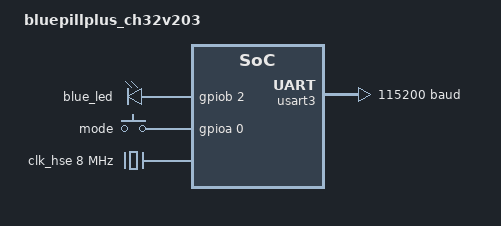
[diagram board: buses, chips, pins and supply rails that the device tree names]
/*
 * Copyright (c) 2025 MASSDRIVER EI (massdriver.space)
 * SPDX-License-Identifier: Apache-2.0
 */

/dts-v1/;

#include <wch/ch32v203/ch32v203c8t.dtsi>
#include <zephyr/dt-bindings/gpio/gpio.h>
#include <zephyr/dt-bindings/input/input-event-codes.h>
#include "bluepillplus_ch32v203-pinctrl.dtsi"

/ {
	model = "bluepillplus_ch32v203";
	compatible = "wch,ch32v203";

	chosen {
		zephyr,sram = &sram0;
		zephyr,flash = &flash0;
		zephyr,console = &usart3;
		zephyr,shell-uart = &usart3;
	};

	leds {
		compatible = "gpio-leds";
		status = "okay";

		blue_led: led0 {
			gpios = <&gpiob 2 GPIO_ACTIVE_HIGH>;
		};
	};

	buttons {
		compatible = "gpio-keys";

		mode: sw0 {
			gpios = <&gpioa 0 GPIO_ACTIVE_HIGH>;
			zephyr,code = <INPUT_KEY_0>;
		};
	};

	aliases {
		led0 = &blue_led;
		sw0 = &mode;
	};
};

&clk_hse {
	clock-frequency = <DT_FREQ_M(8)>;
	status = "okay";
};

&pll {
	clocks = <&clk_hse>;
	status = "okay";
};

&rcc {
	clocks = <&pll>;
};

&gpioa {
	status = "okay";
};

&gpiob {
	status = "okay";
};

&gpioc {
	status = "okay";
};

&usart3 {
	status = "okay";
	current-speed = <115200>;
	pinctrl-0 = <&usart3_default>;
	pinctrl-names = "default";
};
